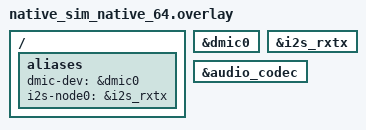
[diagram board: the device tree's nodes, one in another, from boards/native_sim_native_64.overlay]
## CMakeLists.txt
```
#
# Copyright 2025-2026 NXP
#
# SPDX-License-Identifier: Apache-2.0
#

cmake_minimum_required(VERSION 3.20.0)

find_package(Zephyr REQUIRED HINTS $ENV{ZEPHYR_BASE})
project(audio_pipeline)

FILE(GLOB app_sources src/*.c)
target_sources(app PRIVATE ${app_sources})
```

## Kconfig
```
# Copyright 2025-2026 NXP
# SPDX-License-Identifier: Apache-2.0

source "Kconfig.zephyr"

config AUDIO_PIPELINE_NUM_FRAMES
	int "Number of audio frames to process before stopping"
	default 100
	help
	  The pipeline captures and plays back this many audio frames, then
	  reports end-of-stream and stops. Keeps the sample deterministic and
	  bounded (useful for native_sim file-in / file-out validation).

config AUDIO_PIPELINE_GAIN_PERCENT
	int "Gain applied by the gain transform (percent, 100 = unity)"
	default 90
	range 0 1000
	help
	  Gain percentage applied to the audio stream. 0 mutes, 100 is unity
	  (pass-through), values above 100 amplify (and may clip).
```

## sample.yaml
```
sample:
  name: libMP audio pipeline
common:
  tags:
    - audio
    - samples
  platform_allow:
    - native_sim/native/64
  integration_platforms:
    - native_sim/native/64
tests:
  # Lifecycle: pipeline starts, flows frames, reports EOS and stops cleanly.
  # Cheap log-only check; no host-side file verification.
  sample.mp.audio.pipeline.lifecycle:
    harness: console
    harness_config:
      type: multi_line
      ordered: true
      regex:
        - "DMIC capture started"
        - "EOS received from element"
        - "Pipeline stopped"

  # Gain sweep: each scenario fixes CONFIG_AUDIO_PIPELINE_GAIN_PERCENT and the
  # pytest harness asserts the captured output matches the exact Q16.16 math.
  sample.mp.audio.pipeline.gain.unity:
    harness: pytest
    extra_configs:
      - CONFIG_AUDIO_PIPELINE_GAIN_PERCENT=100

  sample.mp.audio.pipeline.gain.half:
    harness: pytest
    extra_configs:
      - CONFIG_AUDIO_PIPELINE_GAIN_PERCENT=50

  sample.mp.audio.pipeline.gain.attenuate:
    harness: pytest
    extra_configs:
      - CONFIG_AUDIO_PIPELINE_GAIN_PERCENT=90

  sample.mp.audio.pipeline.gain.mute:
    harness: pytest
    extra_configs:
      - CONFIG_AUDIO_PIPELINE_GAIN_PERCENT=0

  sample.mp.audio.pipeline.gain.amplify:
    harness: pytest
    extra_configs:
      - CONFIG_AUDIO_PIPELINE_GAIN_PERCENT=200

  sample.mp.audio.pipeline.gain.clip:
    harness: pytest
    extra_configs:
      - CONFIG_AUDIO_PIPELINE_GAIN_PERCENT=1000

  # Missing input file -> DMIC yields silence -> output must be all zeros.
  sample.mp.audio.pipeline.silence:
    harness: pytest
    harness_config:
      pytest_args:
        - "--audio-mode=silence"

  # Short stream (fewer frames than the sink prebuffer threshold) must still be
  # flushed on stop: output frame count must equal the requested frame count.
  sample.mp.audio.pipeline.shortstream:
    harness: pytest
    extra_configs:
      - CONFIG_AUDIO_PIPELINE_NUM_FRAMES=3

  # Same pipeline under AddressSanitizer + UndefinedBehaviorSanitizer.
  sample.mp.audio.pipeline.sanitizers:
    harness: pytest
    extra_configs:
      - CONFIG_ASAN=y
      - CONFIG_UBSAN=y
```

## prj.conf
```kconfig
CONFIG_LOG=y

CONFIG_HEAP_MEM_POOL_SIZE=25000
CONFIG_MAIN_STACK_SIZE=4096

# libMP core + audio plugin
CONFIG_MP=y
# capsfilter lives in the zbase base-elements plugin
CONFIG_MP_PLUGIN_ZBASE=y
CONFIG_MP_CAPSFILTER=y
CONFIG_MP_PLUGIN_ZAUD=y

# Audio subsystems used by the zaud plugin
CONFIG_AUDIO=y
CONFIG_AUDIO_DMIC=y
CONFIG_AUDIO_CODEC=y
CONFIG_I2S=y
```

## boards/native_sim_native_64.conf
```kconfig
CONFIG_AUDIO_DMIC_NATIVE_SIM=y
CONFIG_I2S_NATIVE_SIM=y
CONFIG_AUDIO_CODEC_DUMMY=y

# Deep host queues so the TX prebuffer cushion is not capped by the driver
CONFIG_I2S_NATIVE_SIM_QUEUE_SIZE=32
CONFIG_AUDIO_DMIC_NATIVE_SIM_QUEUE_SIZE=32
```

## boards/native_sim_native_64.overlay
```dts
/*
 * Copyright 2025-2026 NXP
 *
 * SPDX-License-Identifier: Apache-2.0
 */

/*
 * Devicetree contract for the audio pipeline sample. The zaud elements bind
 * their devices through these aliases / node label:
 *   - dmic-dev    : DMIC source device
 *   - i2s-node0   : I2S device driven by the codec sink
 *   - audio_codec : codec node label configured by the sink
 *
 * native_sim already provides file-backed audio nodes, so this overlay only
 * enables them and (re)asserts the aliases the sample relies on.
 */

/ {
	aliases {
		dmic-dev = &dmic0;
		i2s-node0 = &i2s_rxtx;
	};
};

&dmic0 {
	status = "okay";
};

&i2s_rxtx {
	status = "okay";
};

&audio_codec {
	status = "okay";
};
```

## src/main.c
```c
/*
 * Copyright 2025-2026 NXP
 *
 * SPDX-License-Identifier: Apache-2.0
 */

#include <stdint.h>

#include <zephyr/kernel.h>
#include <zephyr/logging/log.h>
#include <zephyr/sys/util.h>

#include <zephyr/mp/core/mp.h>
#include <zephyr/mp/core/mp_bin.h>
#include <zephyr/mp/core/mp_message.h>
#include <zephyr/mp/core/mp_object.h>
#include <zephyr/mp/core/mp_property.h>

#if defined(CONFIG_MP_CAPSFILTER)
#include <zephyr/mp/zbase/mp_capsfilter.h>
#endif

#include <zephyr/mp/zaud/mp_zaud_dmic_src.h>
#include <zephyr/mp/zaud/mp_zaud_gain.h>
#include <zephyr/mp/zaud/mp_zaud_i2s_codec_sink.h>
#include <zephyr/mp/zaud/mp_zaud_property.h>

LOG_MODULE_REGISTER(main, LOG_LEVEL_INF);

#define PIPE_ID        0
#define DMIC_SRC_ID    1
#define CAPS_FILTER_ID 2
#define GAIN_ID        3
#define I2S_SINK_ID    4

/* Capture this many frames then stop the pipeline (deterministic EOS) */
#define NUM_FRAMES        CONFIG_AUDIO_PIPELINE_NUM_FRAMES
/* Audio frame interval in microseconds (10 ms) */
#define FRAME_INTERVAL_US 10000
/* Margin to let queued playback buffers drain before stopping */
#define DRAIN_MARGIN_MS   200

static struct mp_pipeline pipe;
static struct mp_zaud_dmic_src source;
static struct mp_zaud_gain gain;
static struct mp_zaud_i2s_codec_sink sink;
#if defined(CONFIG_MP_CAPSFILTER)
static struct mp_caps_filter caps_filter;
#endif

int main(void)
{
	int gain_val = CONFIG_AUDIO_PIPELINE_GAIN_PERCENT;
	int ret;

	MP_ELEMENT_INIT(&pipe, mp_pipeline_init, PIPE_ID);
	MP_ELEMENT_INIT(&source, mp_zaud_dmic_src_init, DMIC_SRC_ID);
	MP_ELEMENT_INIT(&gain, mp_zaud_gain_init, GAIN_ID);
	MP_ELEMENT_INIT(&sink, mp_zaud_i2s_codec_sink_init, I2S_SINK_ID);

	/* Stop after a fixed number of frames so the pipeline ends deterministically */
	ret = mp_object_set_properties((struct mp_object *)&source, PROP_NUM_BUFS,
				       (void *)(uintptr_t)NUM_FRAMES, PROP_LIST_END);
	if (ret < 0) {
		LOG_ERR("Failed to set source properties");
		return 0;
	}

	ret = mp_object_set_properties((struct mp_object *)&gain, PROP_GAIN, &gain_val,
				       PROP_LIST_END);
	if (ret < 0) {
		LOG_ERR("Failed to set gain properties");
		return 0;
	}

#if defined(CONFIG_MP_CAPSFILTER)
	MP_ELEMENT_INIT(&caps_filter, mp_caps_filter_init, CAPS_FILTER_ID);

	uint32_t frame_interval = FRAME_INTERVAL_US;
	struct mp_caps *caps = mp_caps_new(MP_MEDIA_AUDIO_PCM, MP_CAPS_FRAME_INTERVAL, MP_TYPE_UINT,
					   frame_interval, MP_CAPS_END);

	if (caps == NULL) {
		LOG_ERR("Failed to create caps");
		return 0;
	}

	ret = mp_object_set_properties((struct mp_object *)&caps_filter, PROP_CAPS, caps,
				       PROP_LIST_END);
	mp_caps_unref(caps);
	if (ret < 0) {
		LOG_ERR("Failed to set caps filter properties");
		return 0;
	}
#endif

	if (mp_bin_add((struct mp_bin *)&pipe,
		       (struct mp_element *)&source,
		       IF_ENABLED(CONFIG_MP_CAPSFILTER, ((struct mp_element *)&caps_filter,))
		       (struct mp_element *)&gain,
		       (struct mp_element *)&sink, NULL) != 0) {
		LOG_ERR("Failed to add elements to the pipeline");
		return 0;
	}

	if (mp_element_link((struct mp_element *)&source,
			    IF_ENABLED(CONFIG_MP_CAPSFILTER, ((struct mp_element *)&caps_filter,))
			    (struct mp_element *)&gain,
			    (struct mp_element *)&sink, NULL) != 0) {
		LOG_ERR("Failed to link elements");
		return 0;
	}

	LOG_INF("Starting audio pipeline (%d frames)", NUM_FRAMES);

	if (mp_element_set_state((struct mp_element *)&pipe, MP_STATE_PLAYING) !=
	    MP_STATE_CHANGE_SUCCESS) {
		LOG_ERR("Failed to start pipeline");
		return 0;
	}

	/* Block until the pipeline reports end-of-stream or an error */
	struct mp_bus *bus = mp_element_get_bus((struct mp_element *)&pipe);
	struct mp_message msg;

	if (mp_bus_pop_msg(bus, MP_MESSAGE_ERROR | MP_MESSAGE_EOS, &msg) == 0) {
		switch (msg.type) {
		case MP_MESSAGE_EOS:
			LOG_INF("EOS received from element %d", msg.origin->object.id);
			break;
		case MP_MESSAGE_ERROR:
			LOG_ERR("ERROR received from element %d", msg.origin->object.id);
			break;
		default:
			LOG_WRN("unexpected message (type %u) from element %d", msg.type,
				msg.origin->object.id);
			break;
		}
	}

	/*
	 * Pause first (this also flushes any sink buffers queued by a stream too
	 * short to have hit the playback start threshold), let them drain, then
	 * stop the pipeline cleanly.
	 */
	mp_element_set_state((struct mp_element *)&pipe, MP_STATE_PAUSED);
	k_msleep(DRAIN_MARGIN_MS);

	if (mp_element_set_state((struct mp_element *)&pipe, MP_STATE_READY) !=
	    MP_STATE_CHANGE_SUCCESS) {
		LOG_ERR("Failed to stop pipeline cleanly");
		return 0;
	}

	LOG_INF("Pipeline stopped");

	return 0;
}
```
